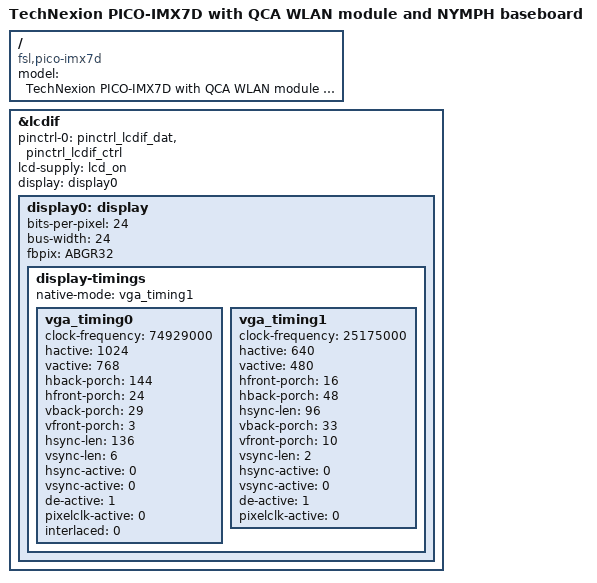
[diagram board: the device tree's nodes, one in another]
/*
 * Copyright 2018 Technexion Ltd.
 *
 * Author: Tapani Utriainen <tapani@technexion.com>
 *	   Richard Hu <richard.hu@technexion.com>
 *
 * This program is free software; you can redistribute it and/or modify
 * it under the terms of the GNU General Public License version 2 as
 * published by the Free Software Foundation.
 *
 */
/dts-v1/;

#include "imx7d.dtsi"
#include "imx7d-pico-qca.dtsi"
#include "baseboard_pico_nymph.dtsi"
/ {
	model = "TechNexion PICO-IMX7D with QCA WLAN module and NYMPH baseboard";
	compatible = "fsl,pico-imx7d", "fsl,imx7d";
};

&lcdif {
	pinctrl-names = "default";
	pinctrl-0 = <&pinctrl_lcdif_dat
		&pinctrl_lcdif_ctrl>;
	lcd-supply = <&lcd_on>;
	display = <&display0>;
	status = "okay";

	display0: display {
		bits-per-pixel = <24>;
		bus-width = <24>;
		fbpix = "ABGR32";

		display-timings {
			native-mode = <&vga_timing1>;
			vga_timing0: vga_timing0 {
				clock-frequency = <74929000>;
				hactive = <1024>;
				vactive = <768>;
				hback-porch = <144>;
				hfront-porch = <24>;
				vback-porch = <29>;
				vfront-porch = <3>;
				hsync-len = <136>;
				vsync-len = <6>;
				hsync-active = <0>;
				vsync-active = <0>;
				de-active = <1>;
				pixelclk-active = <0>;
				interlaced =  <0>;
			};
			/* we have to boost this to something like 28.285MHz to get output close to this */
			vga_timing1: vga_timing1 {
				clock-frequency = <25175000>;
				hactive = <640>;
				vactive = <480>;
				hfront-porch = <16>;
				hback-porch = <48>;
				hsync-len = <96>;
				vback-porch = <33>;
				vfront-porch = <10>;
				vsync-len = <2>;
				hsync-active = <0>;
				vsync-active = <0>;
				de-active = <1>;
				pixelclk-active = <0>;
			};
		};
	};
};
